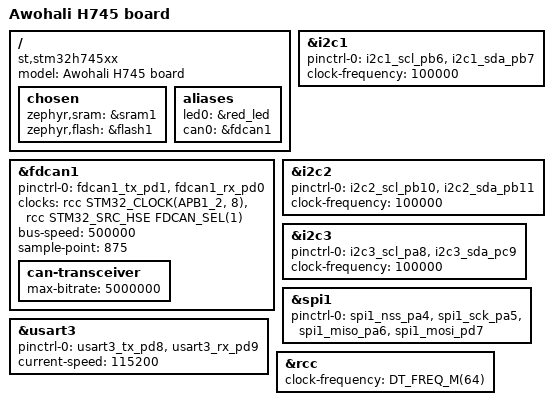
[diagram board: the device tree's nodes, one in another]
/*
 * Copyright (c) 2020 Alexander Kozhinov <ak.alexander.kozhinov@gmail.com>
 * Copyright (c) 2024 Tomas Jurena <jurena@utb.cz>
 *
 * SPDX-License-Identifier: Apache-2.0
 */

/dts-v1/;
#include <st/h7/stm32h745Xi_m4.dtsi>
#include "awohali_h745.dtsi"

/ {
	model = "Awohali H745 board";
	compatible = "st,stm32h745xx";

	/* HW resources belonging to CM4 */
	chosen {
		zephyr,sram = &sram1;
		zephyr,flash = &flash1;
	};

	aliases {
		led0 = &red_led;
		can0 = &fdcan1;
	};
};

&fdcan1 {
	pinctrl-0 = <&fdcan1_tx_pd1 &fdcan1_rx_pd0>;
	pinctrl-names = "default";
	clocks = <&rcc STM32_CLOCK(APB1_2, 8)>,
		<&rcc STM32_SRC_HSE FDCAN_SEL(1)>;
	bus-speed = <500000>;
	sample-point = <875>;
	status = "okay";

	can-transceiver {
		max-bitrate = <5000000>;
	};
};

&i2c1 {
	pinctrl-0 = <&i2c1_scl_pb6 &i2c1_sda_pb7>;
	pinctrl-names = "default";
	clock-frequency = <100000>;
	status = "okay";
};

&i2c2 {
	pinctrl-0 = <&i2c2_scl_pb10 &i2c2_sda_pb11>;
	pinctrl-names = "default";
	clock-frequency = <100000>;
	status = "okay";
};

&i2c3 {
	pinctrl-0 = <&i2c3_scl_pa8 &i2c3_sda_pc9>;
	pinctrl-names = "default";
	clock-frequency = <100000>;
	status = "okay";
};

&spi1 {
	pinctrl-0 = <&spi1_nss_pa4 &spi1_sck_pa5 &spi1_miso_pa6 &spi1_mosi_pd7>;
	pinctrl-names = "default";
	status = "okay";
};

&usart3 {
	pinctrl-0 = <&usart3_tx_pd8 &usart3_rx_pd9>;
	pinctrl-names = "default";
	current-speed = <115200>;
	status = "okay";
};

&rcc {
	clock-frequency = <DT_FREQ_M(64)>;
};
